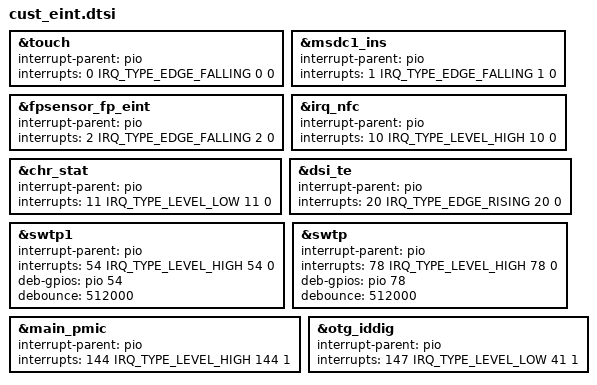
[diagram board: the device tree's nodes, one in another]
/*
 * Generated by MTK SP DrvGen Version: 3.5.160809 for MT6765.
 * 2023-08-23 20:59:31
 * Do Not Modify The File.
 * Copyright Mediatek Inc. (c) 2016.
*/

/*************************
 * EINT DTSI File
*************************/

#include <dt-bindings/interrupt-controller/irq.h>
#include <dt-bindings/interrupt-controller/arm-gic.h>

&touch {
	interrupt-parent = <&pio>;
	interrupts = <0 IRQ_TYPE_EDGE_FALLING 0 0>;
	status = "okay";
};

&msdc1_ins {
	interrupt-parent = <&pio>;
	interrupts = <1 IRQ_TYPE_EDGE_FALLING 1 0>;
	status = "okay";
};

&fpsensor_fp_eint {
	interrupt-parent = <&pio>;
	interrupts = <2 IRQ_TYPE_EDGE_FALLING 2 0>;
	status = "okay";
};

&irq_nfc {
	interrupt-parent = <&pio>;
	interrupts = <10 IRQ_TYPE_LEVEL_HIGH 10 0>;
	status = "okay";
};

&chr_stat {
	interrupt-parent = <&pio>;
	interrupts = <11 IRQ_TYPE_LEVEL_LOW 11 0>;
	status = "okay";
};

&dsi_te {
	interrupt-parent = <&pio>;
	interrupts = <20 IRQ_TYPE_EDGE_RISING 20 0>;
	status = "okay";
};

&swtp1 {
	interrupt-parent = <&pio>;
	interrupts = <54 IRQ_TYPE_LEVEL_HIGH 54 0>;
	deb-gpios = <&pio 54 0>;
	debounce = <512000>;
	status = "okay";
};

&swtp {
	interrupt-parent = <&pio>;
	interrupts = <78 IRQ_TYPE_LEVEL_HIGH 78 0>;
	deb-gpios = <&pio 78 0>;
	debounce = <512000>;
	status = "okay";
};

&main_pmic {
	interrupt-parent = <&pio>;
	interrupts = <144 IRQ_TYPE_LEVEL_HIGH 144 1>;
	status = "okay";
};

&otg_iddig {
	interrupt-parent = <&pio>;
	interrupts = <147 IRQ_TYPE_LEVEL_LOW 41 1>;
	status = "okay";
};

